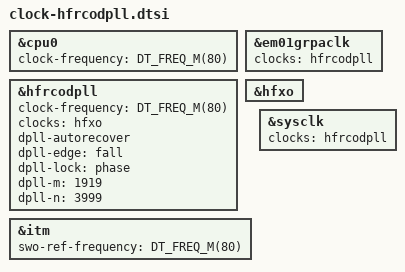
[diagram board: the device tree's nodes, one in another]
/*
 * Copyright (c) 2026 Silicon Laboratories Inc.
 *
 * SPDX-License-Identifier: Apache-2.0
 */

&cpu0 {
	clock-frequency = <DT_FREQ_M(80)>;
};

&em01grpaclk {
	clocks = <&hfrcodpll>;
};

&hfrcodpll {
	clock-frequency = <DT_FREQ_M(80)>;
	clocks = <&hfxo>;
	dpll-autorecover;
	dpll-edge = "fall";
	dpll-lock = "phase";
	dpll-m = <1919>;
	dpll-n = <3999>;
};

&hfxo {
	status = "okay";
};

&itm {
	swo-ref-frequency = <DT_FREQ_M(80)>;
};

&sysclk {
	clocks = <&hfrcodpll>;
};
